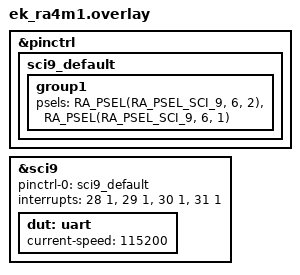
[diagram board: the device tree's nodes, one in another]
/*
 * Copyright (c) 2025 Renesas Electronics Corporation
 * SPDX-License-Identifier: Apache-2.0
 */

&pinctrl {
	sci9_default: sci9_default {
		group1 {
			/* tx rx */
			psels = <RA_PSEL(RA_PSEL_SCI_9, 6, 2)>,
			<RA_PSEL(RA_PSEL_SCI_9, 6, 1)>;
		};
	};
};

&sci9 {
	pinctrl-0 = <&sci9_default>;
	pinctrl-names = "default";
	interrupts = <28 1>, <29 1>, <30 1>, <31 1>;
	interrupt-names = "rxi", "txi", "tei", "eri";
	status = "okay";
	dut: uart {
		current-speed = <115200>;
		status = "okay";
	};
};
